AUTOSAR XML (schema 4-2-2)
package /ComponentTypes
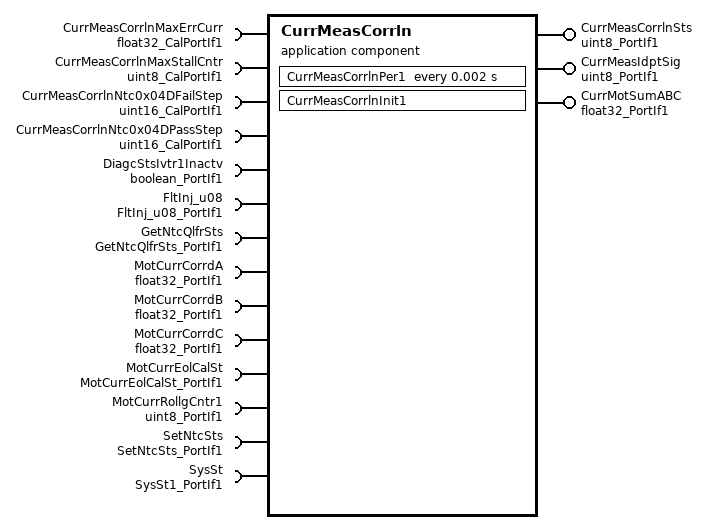
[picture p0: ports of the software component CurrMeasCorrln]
  application sw component type CurrMeasCorrln
    provide port CurrMeasCorrlnSts: nonqueued-sender-com-spec{data-element=Val, init-value=63}, provided-interface=uint8_PortIf1
    provide port CurrMeasIdptSig: nonqueued-sender-com-spec{data-element=Val, init-value=2}, provided-interface=uint8_PortIf1
    provide port CurrMotSumABC: nonqueued-sender-com-spec{data-element=Val, init-value=0}, provided-interface=float32_PortIf1
    14 x require port:
      CurrMeasCorrlnMaxErrCurr: parameter-require-com-spec{init-value=12, parameter=Val}, required-interface=float32_CalPortIf1
      CurrMeasCorrlnMaxStallCntr: parameter-require-com-spec{init-value=200, parameter=Val}, required-interface=uint8_CalPortIf1
      CurrMeasCorrlnNtc0x04DFailStep: parameter-require-com-spec{init-value=512, parameter=Val}, required-interface=uint16_CalPortIf1
      CurrMeasCorrlnNtc0x04DPassStep: parameter-require-com-spec{init-value=512, parameter=Val}, required-interface=uint16_CalPortIf1
      DiagcStsIvtr1Inactv: nonqueued-receiver-com-spec{data-element=Logl, filter=data-filter-type=ALWAYS, init-value=0}, required-interface=boolean_PortIf1
      FltInj_u08: client-com-spec=Oper, required-interface=FltInj_u08_PortIf1
      GetNtcQlfrSts: client-com-spec=Oper, required-interface=GetNtcQlfrSts_PortIf1
      MotCurrCorrdA: nonqueued-receiver-com-spec{data-element=Val, filter=data-filter-type=ALWAYS, init-value=0}, required-interface=float32_PortIf1
      MotCurrCorrdB: nonqueued-receiver-com-spec{data-element=Val, filter=data-filter-type=ALWAYS, init-value=0}, required-interface=float32_PortIf1
      MotCurrCorrdC: nonqueued-receiver-com-spec{data-element=Val, filter=data-filter-type=ALWAYS, init-value=0}, required-interface=float32_PortIf1
      MotCurrEolCalSt: nonqueued-receiver-com-spec{data-element=Val, filter=data-filter-type=ALWAYS, init-value=0}, required-interface=MotCurrEolCalSt_PortIf1
      MotCurrRollgCntr1: nonqueued-receiver-com-spec{data-element=Val, filter=data-filter-type=ALWAYS, init-value=0}, required-interface=uint8_PortIf1
      SetNtcSts: client-com-spec=Oper, required-interface=SetNtcSts_PortIf1
      SysSt: nonqueued-receiver-com-spec{data-element=Val, filter=data-filter-type=ALWAYS, init-value=3}, required-interface=SysSt1_PortIf1
    behavior CurrMeasCorrln_InternalBehavior
      ar-typed-per-instance-memorys:
        data LongTermCorrlnStsABC: sw-calibration-access=READ-ONLY, type=boolean
        data Snsr0RollgCntPrev: sw-calibration-access=READ-ONLY, type=uint8
        data Snsr0StallCntPrev: sw-calibration-access=READ-ONLY, type=uint8
      init event CurrMeasCorrln_InitEvent: start-on-event=CurrMeasCorrlnInit1
      timing event TMT_CurrMeasCorrlnPer1: start-on-event=CurrMeasCorrlnPer1, period=0.002
      port-api-options:
        enable-take-address=false, error-handling=NO-TRANSFORMER-ERROR-HANDLING, indirect-api=false, port=CurrMeasCorrlnMaxErrCurr
        enable-take-address=false, error-handling=NO-TRANSFORMER-ERROR-HANDLING, indirect-api=false, port=CurrMeasCorrlnNtc0x04DPassStep
        enable-take-address=false, error-handling=NO-TRANSFORMER-ERROR-HANDLING, indirect-api=false, port=CurrMeasCorrlnSts
        enable-take-address=false, error-handling=NO-TRANSFORMER-ERROR-HANDLING, indirect-api=false, port=CurrMeasIdptSig
        enable-take-address=false, error-handling=NO-TRANSFORMER-ERROR-HANDLING, indirect-api=false, port=CurrMotSumABC
        enable-take-address=false, error-handling=NO-TRANSFORMER-ERROR-HANDLING, indirect-api=false, port=DiagcStsIvtr1Inactv
        enable-take-address=false, error-handling=NO-TRANSFORMER-ERROR-HANDLING, indirect-api=false, port=FltInj_u08
        enable-take-address=false, error-handling=NO-TRANSFORMER-ERROR-HANDLING, indirect-api=false, port=GetNtcQlfrSts
        enable-take-address=false, error-handling=NO-TRANSFORMER-ERROR-HANDLING, indirect-api=false, port=MotCurrCorrdA
        enable-take-address=false, error-handling=NO-TRANSFORMER-ERROR-HANDLING, indirect-api=false, port=MotCurrCorrdB
        enable-take-address=false, error-handling=NO-TRANSFORMER-ERROR-HANDLING, indirect-api=false, port=MotCurrCorrdC
        enable-take-address=false, error-handling=NO-TRANSFORMER-ERROR-HANDLING, indirect-api=false, port=MotCurrEolCalSt
        enable-take-address=false, error-handling=NO-TRANSFORMER-ERROR-HANDLING, indirect-api=false, port=MotCurrRollgCntr1
        enable-take-address=false, error-handling=NO-TRANSFORMER-ERROR-HANDLING, indirect-api=false, port=SetNtcSts
      runnable CurrMeasCorrlnInit1
      runnable CurrMeasCorrlnPer1
        data-receive-point-by-arguments:
          7 x access:
            REC_DiagcStsIvtr1Inactv_Logl: accessed-variable=DiagcStsIvtr1Inactv.Logl
            REC_MotCurrCorrdA_Val: accessed-variable=MotCurrCorrdA.Val
            REC_MotCurrCorrdB_Val: accessed-variable=MotCurrCorrdB.Val
            REC_MotCurrCorrdC_Val: accessed-variable=MotCurrCorrdC.Val
            REC_MotCurrEolCalSt_Val: accessed-variable=MotCurrEolCalSt.Val
            REC_MotCurrRollgCntr1_Val: accessed-variable=MotCurrRollgCntr1.Val
            REC_SysSt_Val: accessed-variable=SysSt.Val
        data-send-points:
          access SEND_CurrMeasCorrlnSts_Val: accessed-variable=CurrMeasCorrlnSts.Val
          access SEND_CurrMeasIdptSig_Val: accessed-variable=CurrMeasIdptSig.Val
          access SEND_CurrMotSumABC_Val: accessed-variable=CurrMotSumABC.Val
        sync call SC_FltInj_u08_Oper: operation=FltInj_u08.Oper, timeout=0
        sync call SC_GetNtcQlfrSts_Oper: operation=GetNtcQlfrSts.Oper, timeout=0
        sync call SC_SetNtcSts_Oper: operation=SetNtcSts.Oper, timeout=0
  swc implementation CurrMeasCorrln_Implementation: behavior=CurrMeasCorrln_InternalBehavior
    code-descriptors:
      code Default: artifact-descriptors=autosar-engineering-object={short-label=Default, category=SWSRC}
